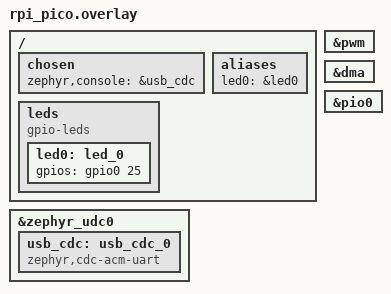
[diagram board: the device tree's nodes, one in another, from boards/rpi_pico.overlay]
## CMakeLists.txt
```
cmake_minimum_required(VERSION 3.20.0)

find_package(Zephyr REQUIRED HINTS $ENV{ZEPHYR_BASE})
project(pico_mplay_zephyr)

target_sources(app PRIVATE src/main.c src/mod_player.c)

# Embed the MOD file as flash data (mod_data[] / mod_data_len), generated at
# build time into the build directory rather than committing a ~6x larger
# generated header - same approach as ~/devel/pico_mplay. Swap songs by
# changing MOD_SOURCE_FILE.
set(MOD_SOURCE_FILE ${CMAKE_CURRENT_LIST_DIR}/AXEL_F.MOD)
set(MOD_DATA_HEADER ${CMAKE_CURRENT_BINARY_DIR}/mod_data.h)
add_custom_command(
        OUTPUT ${MOD_DATA_HEADER}
        COMMAND ${CMAKE_COMMAND} -E copy ${MOD_SOURCE_FILE} mod_data
        COMMAND sh -c "xxd -i mod_data | sed \
                -e 's/^unsigned char mod_data\\[\\]/static const unsigned char mod_data[]/' \
                -e 's/^unsigned int mod_data_len/static const unsigned int mod_data_len/' \
                > mod_data.h"
        WORKING_DIRECTORY ${CMAKE_CURRENT_BINARY_DIR}
        DEPENDS ${MOD_SOURCE_FILE}
        VERBATIM
        COMMENT "Generating mod_data.h from ${MOD_SOURCE_FILE}"
)
add_custom_target(mod_data_header DEPENDS ${MOD_DATA_HEADER})
add_dependencies(app mod_data_header)
target_include_directories(app PRIVATE ${CMAKE_CURRENT_BINARY_DIR})
```

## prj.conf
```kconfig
CONFIG_GPIO=y
CONFIG_PWM=y
CONFIG_DMA=y

# For serial console (as of autumn 2026)
CONFIG_USB_DEVICE_STACK_NEXT=y
CONFIG_CDC_ACM_SERIAL_INITIALIZE_AT_BOOT=y
CONFIG_STDOUT_CONSOLE=y
CONFIG_SERIAL=y
CONFIG_UART_LINE_CTRL=y
CONFIG_USBD_CDC_ACM_CLASS=y
```

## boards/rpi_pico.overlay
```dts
/*
 * Neither rpi_pico nor rpi_pico2 define a `led0` alias in this Zephyr tree,
 * so the standard samples/basic/blinky-style DT_ALIAS(led0) pattern needs
 * this one-time overlay. GPIO25 is the onboard LED on the plain (non-W)
 * Pico 2, same pin as the original Pico.
 */
#include <zephyr/dt-bindings/gpio/gpio.h>

/ {
    chosen {
        zephyr,console = &usb_cdc;
    };

    aliases {
		led0 = &led0;
	};

	leds {
		compatible = "gpio-leds";
		led0: led_0 {
			gpios = <&gpio0 25 GPIO_ACTIVE_HIGH>;
		};
	};
};

/*
 * Both disabled by default; pinctrl (GPIO25 -> PWM slice 4 channel B) is
 * already wired up at board level (pwm_ch4b_default), so enabling status is
 * all that's needed here.
 */
&pwm {
	status = "okay";
};

&dma {
	status = "okay";
};

/*
 * No pinctrl group needed here: i2s_out_program_init()-equivalent code in
 * main.c routes GP26/27/28 to the PIO block via raw pico_gpio_init() calls
 * (same as the bare-metal version), bypassing Zephyr's pinctrl subsystem
 * entirely for this peripheral.
 */
&pio0 {
	status = "okay";
};

&zephyr_udc0 {
    usb_cdc: usb_cdc_0 {
        compatible = "zephyr,cdc-acm-uart";
    };
};
```

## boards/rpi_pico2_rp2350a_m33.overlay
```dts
/*
 * Neither rpi_pico nor rpi_pico2 define a `led0` alias in this Zephyr tree,
 * so the standard samples/basic/blinky-style DT_ALIAS(led0) pattern needs
 * this one-time overlay. GPIO25 is the onboard LED on the plain (non-W)
 * Pico 2, same pin as the original Pico.
 */
#include <zephyr/dt-bindings/gpio/gpio.h>

/ {
	aliases {
		led0 = &led0;
	};

	leds {
		compatible = "gpio-leds";
		led0: led_0 {
			gpios = <&gpio0 25 GPIO_ACTIVE_HIGH>;
		};
	};
};

/*
 * Both disabled by default; pinctrl (GPIO25 -> PWM slice 4 channel B) is
 * already wired up at board level (pwm_ch4b_default), so enabling status is
 * all that's needed here.
 */
&pwm {
	status = "okay";
};

&dma {
	status = "okay";
};
```

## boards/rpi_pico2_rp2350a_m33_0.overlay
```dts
/*
 * Neither rpi_pico nor rpi_pico2 define a `led0` alias in this Zephyr tree,
 * so the standard samples/basic/blinky-style DT_ALIAS(led0) pattern needs
 * this one-time overlay. GPIO25 is the onboard LED on the plain (non-W)
 * Pico 2, same pin as the original Pico.
 */
#include <zephyr/dt-bindings/gpio/gpio.h>

/ {
	chosen {
		zephyr,console = &usb_cdc;
	};

	aliases {
		led0 = &led0;
	};

	leds {
		compatible = "gpio-leds";
		led0: led_0 {
			gpios = <&gpio0 25 GPIO_ACTIVE_HIGH>;
		};
	};
};

/*
 * Both disabled by default; pinctrl (GPIO25 -> PWM slice 4 channel B) is
 * already wired up at board level (pwm_ch4b_default), so enabling status is
 * all that's needed here.
 */
&pwm {
	status = "okay";
};

&dma {
	status = "okay";
};

/*
 * No pinctrl group needed here: i2s_out_program_init()-equivalent code in
 * main.c routes GP26/27/28 to the PIO block via raw pico_gpio_init() calls
 * (same as the bare-metal version), bypassing Zephyr's pinctrl subsystem
 * entirely for this peripheral.
 */
&pio0 {
	status = "okay";
};

&zephyr_udc0 {
	usb_cdc: usb_cdc_0 {
		compatible = "zephyr,cdc-acm-uart";
	};
};
```

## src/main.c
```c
/*
 * Step 4: real Amiga MOD playback, same PIO/DMA I2S backend as step 3.
 *
 * mod_player.c/h (ported here unmodified from ~/devel/pico_mplay - it was
 * already pure C with zero pico-sdk/Zephyr dependency) replaces the sweep
 * generator as the sample source. mod_player_produce() doesn't care how
 * many samples are requested or when, so it drops straight into
 * fill_buffer() exactly like it does in the bare-metal version - the only
 * change from step 3 is what fill_buffer() calls to get mono samples
 * before packing them into stereo I2S frames.
 *
 * Reuses ~/devel/pico_mplay's i2s_out.pio verbatim (see i2s_out_pio.h) via
 * Zephyr's pio_rpi_pico driver, which handles state-machine allocation and
 * program loading but - like Zephyr's PWM API in step 2 - has no concept
 * of a DMA-fed streaming consumer for a custom PIO program. So the pattern
 * is the same as step 2: Zephyr's driver does the one-time setup (here,
 * allocating the SM and loading the program), then DMA is configured and
 * manually re-armed from its own completion callback via zephyr/drivers/dma.h,
 * writing 32-bit stereo frames directly into the PIO's TX FIFO register.
 *
 * dma_done() (the DMA completion ISR) only re-arms DMA and does bookkeeping
 * (consumed/filled sequence counters, an underrun count, and the PIO's own
 * TXSTALL flag) - it does not render. Rendering (fill_buffer(), i.e. the
 * whole 4-channel mixer) runs in main()'s thread, woken by a semaphore the
 * ISR gives, so a slow render can't block other same/lower-priority
 * interrupts (e.g. USB CDC) for the whole mixer's runtime. See the
 * consumed/filled comment near their declarations for why a single flag
 * isn't enough, and ~/devel/pico_dma/pico_mplay.c for the bare-metal
 * version of the same scheme this was ported from.
 *
 * pio_gpio_init()/pio_sm_set_consecutive_pindirs() (raw pico-sdk calls, same
 * as the bare-metal version) handle routing GP26/27/28 to the PIO block
 * directly - no Zephyr pinctrl devicetree group needed for this peripheral.
 *
 * The MOD file (mod_data[]/mod_data_len) is generated at build time from
 * AXEL_F.MOD into the build directory - see CMakeLists.txt.
 */

#include <zephyr/kernel.h>
#include <zephyr/device.h>
#include <zephyr/drivers/dma.h>
#include <zephyr/sys/barrier.h>
#include <zephyr/drivers/misc/pio_rpi_pico/pio_rpi_pico.h>
#if defined(CONFIG_SOC_SERIES_RP2350)
#include <zephyr/dt-bindings/dma/rpi-pico-dma-rp2350.h>
#else
#include <zephyr/dt-bindings/dma/rpi-pico-dma-rp2040.h>
#endif
#include <hardware/pio.h>
/*
 * pico-sdk's hardware/pio.h #defines pio0/pio1 as its own PIO-instance
 * singletons (`#define pio0 pio0_hw`), which collides with Zephyr's
 * DT_NODELABEL(pio0) token-pasting macro below - both want the bare
 * identifier. We never use the pico-sdk singletons (PIO comes from
 * pio_rpi_pico_get_pio() instead), so just get them out of the way.
 */
#undef pio0
#undef pio1
#include <hardware/clocks.h>

#include "i2s_out_pio.h"
#include "mod_player.h"
#include "mod_data.h"

#define PIN_BCLK 26   /* WS/LRCLK is PIN_BCLK+1 (GP27) - side-set requirement */
#define PIN_DATA 28

#define SAMPLE_RATE_HZ   48000u
#define BITS_PER_CHANNEL 16u

#define BUF_LEN 256   /* stereo frames/buffer */

static const struct device *dma_dev;
static PIO pio;
static size_t sm;
static uint32_t dma_channel;
static volatile uint32_t *txf;

static uint32_t buf[2][BUF_LEN];

/* Buffers are numbered by sequence: buffer k lives in buf[k & 1]. The DMA
 * ISR (dma_done()) advances `consumed` (buffers DMA has finished) and
 * re-arms the next one immediately; the main thread advances `filled`
 * (buffers completely rendered) only *after* rendering, so comparing the
 * two counters catches every underrun - including DMA reaching a buffer
 * the main thread is still mid-render on. Mirrors the bare-metal version's
 * consumed/filled scheme in ~/devel/pico_dma/pico_mplay.c, and for the same
 * reason: a single "fill_needed" flag cleared before rendering starts can
 * miss/lose events across the ISR/thread boundary.
 *
 * Unlike bare-metal, rendering used to happen directly inside dma_done()
 * itself (the DMA completion ISR) - the entire 4-channel mixer ran with
 * this interrupt's priority blocked for however long mod_player_produce()
 * took, every 5.33ms. That's moved to the main thread below so a slow
 * render can't stall other interrupts (USB CDC console included).
 */
static volatile uint32_t consumed;   /* ISR-owned */
static volatile uint32_t filled;     /* main-thread-owned */
static volatile uint32_t underrun_count;

/* Hardware's own "FIFO ran dry" flag (PIO's sticky per-SM TXSTALL bit),
 * independent of the consumed/filled bookkeeping above - catches cases the
 * software counters can't, such as the main thread being descheduled
 * entirely rather than merely running behind.
 */
static volatile uint32_t txstall_count;
static volatile uint32_t dma_error_count;

K_SEM_DEFINE(fill_needed_sem, 0, 1);

static struct PlayerState player;
static int16_t mono_scratch[BUF_LEN];

/* Renders BUF_LEN mono samples from the MOD mixer, then packs each one into
 * a stereo I2S frame (same value in both channels) matching what
 * i2s_out.pio expects from the FIFO: [left:16][right:16] in one 32-bit word.
 */
static void fill_buffer(uint32_t *b)
{
	mod_player_produce(&player, mono_scratch, BUF_LEN);
	for (int i = 0; i < BUF_LEN; i++) {
		uint16_t sample = (uint16_t)mono_scratch[i];
		b[i] = ((uint32_t)sample << 16) | sample;
	}
}

/* Fires once DMA finishes streaming one of the two buffers. Immediately
 * hands the next buffer (already rendered last time round) back to DMA to
 * keep the gap minimal, bumps the sequence counters, and wakes the main
 * thread to render the buffer that just finished playing - it does *not*
 * render here itself (see the consumed/filled comment above for why).
 */
static void dma_done(const struct device *dev, void *user_data, uint32_t channel, int status);

/* File-scope so dma_done() can re-arm through them (see arm_next_buffer()). */
static struct dma_block_config dma_block = {
	.block_size = BUF_LEN * sizeof(uint32_t),
	.source_addr_adj = DMA_ADDR_ADJ_INCREMENT,
	.dest_addr_adj = DMA_ADDR_ADJ_NO_CHANGE,
};
static struct dma_config dma_cfg = {
	.channel_direction = MEMORY_TO_PERIPHERAL,
	.source_data_size = 4,
	.dest_data_size = 4,
	.source_burst_length = 1,
	.dest_burst_length = 1,
	.block_count = 1,
	.head_block = &dma_block,
	.dma_callback = dma_done,
};

/* Points the (idle) channel at buffer `next & 1` and triggers it - exactly
 * once. This used to be dma_reload() + dma_start(), but on the rpi_pico DMA
 * driver *both* call dma_channel_configure(..., trigger=true), so the second
 * rewrote READ_ADDR/TRANS_COUNT/CTRL_TRIG on a channel already running,
 * racing its DREQ. In xiao_rp2040_mplay (same code, PWM-paced) that race
 * permanently stalled the DMA once every few seconds to minutes; the
 * bare-metal pico_dma never had it (one dma_channel_transfer_from_buffer_now()
 * per buffer). dma_config() only stores settings in the driver - no register
 * writes - so config + start is a single trigger on an idle channel.
 */
static void arm_next_buffer(uint32_t next)
{
	dma_block.source_address = (uintptr_t)buf[next & 1];
	dma_config(dma_dev, dma_channel, &dma_cfg);
	dma_start(dma_dev, dma_channel);
}

static void dma_done(const struct device *dev, void *user_data, uint32_t channel, int status)
{
	ARG_UNUSED(dev);
	ARG_UNUSED(user_data);
	ARG_UNUSED(channel);
	if (status < 0) {
		/* Count it but keep going - returning here without re-arming
		 * silenced audio permanently.
		 */
		dma_error_count++;
	}

	uint32_t next = consumed + 1;   /* sequence number of the buffer to play now */

	arm_next_buffer(next);

	/* `next` must be completely rendered by now (filled > next). If the
	 * main thread hasn't finished it - or hasn't started - DMA is about
	 * to play stale data.
	 */
	if ((int32_t)(filled - next) <= 0) {   /* signed diff: wrap-safe */
		underrun_count++;
	}
	consumed = next;

	uint32_t stall_bit = 1u << (PIO_FDEBUG_TXSTALL_LSB + sm);
	if (pio->fdebug & stall_bit) {
		/* The very first call is special: pio_sm_set_enabled() runs
		 * before dma_start()'s first bus transfer has necessarily
		 * landed in the FIFO, so the SM always stalls briefly at
		 * boot waiting for that first word - not a real underrun.
		 * By the time a whole buffer's worth of playback has elapsed
		 * (i.e. we're here at all), that transient is long over, so
		 * checking here instead of right after the initial
		 * dma_start() in main() is race-free: clear and don't count
		 * once, then count for real from then on.
		 */
		static bool first_call = true;

		if (!first_call) {
			txstall_count++;
		}
		first_call = false;
		pio->fdebug = stall_bit;   /* write-1-to-clear */
	}

	k_sem_give(&fill_needed_sem);
}

int main(void)
{
	/* &pio0 and &dma are enabled in the per-board overlays under boards/;
	 * pio_dev only exists to allocate a state machine and get the raw
	 * PIO handle - everything else is driven through direct pico-sdk
	 * calls below.
	 */
	const struct device *pio_dev = DEVICE_DT_GET(DT_NODELABEL(pio0));

	dma_dev = DEVICE_DT_GET(DT_NODELABEL(dma));

	if (!device_is_ready(pio_dev) || !device_is_ready(dma_dev)) {
		printk("pio or dma device not ready\n");
		return 0;
	}

	pio = pio_rpi_pico_get_pio(pio_dev);
	if (pio_rpi_pico_allocate_sm(pio_dev, &sm) != 0) {
		printk("no free PIO state machine\n");
		return 0;
	}

	/* Load the program bytes from i2s_out_pio.h into PIO instruction
	 * memory and get back where it landed (offset).
	 */
	uint offset = pio_add_program(pio, RPI_PICO_PIO_GET_PROGRAM(i2s_out));

	/* i2s_out.pio spends 2 PIO cycles per bit and 2*BITS_PER_CHANNEL bits
	 * per stereo frame, so the SM must run at SAMPLE_RATE_HZ * 4 *
	 * BITS_PER_CHANNEL to make one frame take exactly one sample period -
	 * same formula as the bare-metal version.
	 */
	float clkdiv = (float)clock_get_hz(clk_sys) / (float)(SAMPLE_RATE_HZ * 4u * BITS_PER_CHANNEL);

	/* Route GP26/27 (BCLK/WS) and GP28 (DATA) to this PIO block and set
	 * them as outputs - raw pico-sdk calls, no Zephyr pinctrl involved.
	 */
	pio_gpio_init(pio, PIN_BCLK);
	pio_gpio_init(pio, PIN_BCLK + 1);
	pio_gpio_init(pio, PIN_DATA);
	pio_sm_set_consecutive_pindirs(pio, sm, PIN_BCLK, 2, true);
	pio_sm_set_consecutive_pindirs(pio, sm, PIN_DATA, 1, true);

	/* Same SM configuration as i2s_out_program_init() in the bare-metal
	 * project's generated header - reconstructed by hand here since
	 * Zephyr's generic RPI_PICO_PIO_DEFINE_PROGRAM macro only captures
	 * wrap_target/wrap, not a program-specific default-config helper.
	 */
	pio_sm_config c = pio_get_default_sm_config();
	sm_config_set_wrap(&c, offset + RPI_PICO_PIO_GET_WRAP_TARGET(i2s_out),
			    offset + RPI_PICO_PIO_GET_WRAP(i2s_out));
	sm_config_set_sideset(&c, 2, false, false);          /* BCLK+WS, 2 bits */
	sm_config_set_sideset_pins(&c, PIN_BCLK);
	sm_config_set_out_pins(&c, PIN_DATA, 1);
	sm_config_set_out_shift(&c, false, true, 32);        /* MSB-first, autopull every 32 bits */
	sm_config_set_fifo_join(&c, PIO_FIFO_JOIN_TX);       /* 8-deep TX FIFO, no RX needed */
	sm_config_set_clkdiv(&c, clkdiv);
	pio_sm_init(pio, sm, offset, &c);

	if (mod_player_init(&player, mod_data, mod_data_len) != 0) {
		printk("mod_player_init failed - bad or unrecognized MOD data\n");
		return 0;
	}

	/* Pre-fill both buffers before DMA/PIO start moving, then remember
	 * the PIO's TX FIFO address as the fixed DMA destination.
	 */
	fill_buffer(buf[0]);
	fill_buffer(buf[1]);
	filled = 2;
	txf = &pio->txf[sm];

	int ch = dma_request_channel(dma_dev, NULL);
	if (ch < 0) {
		printk("no free dma channel\n");
		return 0;
	}
	dma_channel = (uint32_t)ch;

	/* One 32-bit stereo frame per transfer, source address walks buf[0],
	 * destination is the PIO FIFO register and never moves.
	 */
	dma_block.dest_address = (uintptr_t)txf;
	/* dma_slot paces the channel from the PIO SM's own TX DREQ (fires
	 * whenever the FIFO has room), same DREQ pio_get_dreq() would give
	 * the bare-metal version - just wrapped for Zephyr's dma_slot field.
	 */
	dma_cfg.dma_slot = RPI_PICO_DMA_DREQ_TO_SLOT(pio_get_dreq(pio, sm, true));
	dma_block.source_address = (uintptr_t)buf[0];
	dma_config(dma_dev, dma_channel, &dma_cfg);

	/* Enable the SM before the first DMA transfer, same order as the
	 * bare-metal version, so it's already waiting on the FIFO rather
	 * than racing the first transfer.
	 */
	pio_sm_set_enabled(pio, sm, true);
	dma_start(dma_dev, dma_channel);
	/* The SM stalls once at boot, waiting for the first buffer's data to
	 * actually land in the FIFO (dma_start() only arms the transfer, the
	 * bus transaction itself is asynchronous) - that expected transient
	 * is absorbed race-free inside dma_done()'s first call instead of
	 * being cleared here, see the comment there.
	 */

	printk("mod player running\n");
	int64_t next_report = k_uptime_get() + 1000;
	while (1) {
		/* Woken by dma_done() (or times out - not otherwise fatal) so
		 * the report below still fires ~1/s even if nothing is due
		 * to render this tick.
		 */
		k_sem_take(&fill_needed_sem, K_MSEC(100));

		/* Buffer `filled` may be rendered once buffer `filled - 2`
		 * (same slot) has been consumed, i.e. filled < consumed + 2.
		 */
		while ((int32_t)(consumed + 2 - filled) > 0) {
			fill_buffer(buf[filled & 1]);
			barrier_dmem_fence_full();   /* buffer stores land before the count says "done" */
			filled++;
		}

		/* Software-only sanity check, same as bare-metal: position/
		 * row should visibly advance through the song regardless of
		 * whether anything is audible, plus both underrun indicators
		 * (software: render ran late; hardware: FIFO actually ran
		 * dry) so a symptom like an occasional pop can be attributed
		 * to this DMA/render path or ruled out in favour of something
		 * else (e.g. a power-supply issue affecting the amp/DAC).
		 */
		if (k_uptime_get() >= next_report) {
			printk("pos=%d row=%d underruns=%u txstall=%u dma_errs=%u\n",
			       player.current_position, player.current_row,
			       underrun_count, txstall_count, dma_error_count);
			next_report += 1000;
		}
	}
	return 0;
}
```

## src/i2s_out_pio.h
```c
#pragma once

/*
 * Compiled PIO program for i2s_out.pio from ~/devel/pico_mplay (same
 * author, MIT). Zephyr has no pioasm/CMake integration - PIO programs must
 * be embedded as pre-assembled opcode arrays (see RPI_PICO_PIO_DEFINE_PROGRAM
 * below) - so rather than hand-assembling from the ISA reference, these
 * bytes are lifted directly from that project's build/i2s_out.pio.h
 * (pioasm's own output), which is already correct and verified on real
 * hardware, including the BCLK falling/rising-edge fix found there.
 * Regenerate this file from there (rebuild pico_mplay, then
 * `cat build/i2s_out.pio.h`) if that program ever changes.
 *
 * wrap_target=0, wrap=7, side-set width=2 (BCLK+WS) - the generic
 * RPI_PICO_PIO_DEFINE_PROGRAM macro captures the first two; side-set width
 * isn't part of it and has to be set manually via sm_config_set_sideset()
 * wherever this program's default config is built (see main.c).
 *
 * Original .pio source, for reference (see i2s_out.pio in the bare-metal
 * repo for the full explanation of the I2S falling/rising-edge timing this
 * implements - only the short version is repeated here):
 *
 *   .program i2s_out
 *   .side_set 2
 *
 *   .define BITS_PER_CHANNEL 16
 *
 *   .wrap_target
 *   left_word:
 *       set x, (BITS_PER_CHANNEL - 2)  side 0b01   ; BCLK high: samples the previous frame's last bit
 *   left_loop:
 *       out pins, 1                    side 0b00   ; new bit onto DATA, BCLK low (setup)
 *       jmp x-- left_loop              side 0b01   ; BCLK high: receiver samples this bit
 *       out pins, 1                    side 0b10   ; last (16th) left bit; WS flips to "right", BCLK low
 *   right_word:
 *       set x, (BITS_PER_CHANNEL - 2)  side 0b11   ; BCLK high: samples left channel's last bit
 *   right_loop:
 *       out pins, 1                    side 0b10   ; new bit onto DATA, BCLK low (setup)
 *       jmp x-- right_loop             side 0b11   ; BCLK high: receiver samples this bit
 *       out pins, 1                    side 0b00   ; last (16th) right bit; WS flips to "left", BCLK low
 *   .wrap
 *
 * Instruction-by-instruction mapping to the opcodes below (same order):
 *
 *   0xe82e  set  x, 14      side 1   (left_word)
 *   0x6001  out  pins, 1    side 0   (left_loop)
 *   0x0841  jmp  x--, 1     side 1   (left_loop, target = instruction 1)
 *   0x7001  out  pins, 1    side 2   (right_word's leading bit, WS -> right)
 *   0xf82e  set  x, 14      side 3   (right_word)
 *   0x7001  out  pins, 1    side 2   (right_loop)
 *   0x1845  jmp  x--, 5     side 3   (right_loop, target = instruction 5)
 *   0x6001  out  pins, 1    side 0   (last right bit, WS -> left, wraps to 0)
 */

#include <zephyr/drivers/misc/pio_rpi_pico/pio_rpi_pico.h>

RPI_PICO_PIO_DEFINE_PROGRAM(i2s_out, 0, 7,
	0xe82e,
	0x6001,
	0x0841,
	0x7001,
	0xf82e,
	0x7001,
	0x1845,
	0x6001
);
```

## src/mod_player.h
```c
// MOD player core, ported from ~/devel/mplay/mod_player.c (same author, MIT).
// Parsing, effects, and mixing logic is reused near-verbatim; only the
// driving loop and the byte-order-sensitive sample-header handling changed,
// see mod_player.c for why.
#pragma once

#include <stdbool.h>
#include <stddef.h>
#include <stdint.h>

#define MOD_MAX_SAMPLES      32   // 1-indexed: slot 0 unused, 1..31 are real samples
#define MOD_NUM_CHANNELS     4
#define MOD_ROWS_PER_PATTERN 64

struct __attribute__((packed)) ModSample {
    char name[22];
    uint16_t length_words;
    int8_t fine_tune;
    uint8_t volume;
    uint16_t repeat_offset;
    uint16_t repeat_length;
};

struct __attribute__((packed)) ModHeader {
    char title[20];
    struct ModSample samples[31];
    uint8_t pattern_count;
    uint8_t idk;
    uint8_t patterns[128];
    char magic[4];
};

struct ModNote {
    uint8_t  instrument;
    uint16_t period;
    uint8_t  effect;
    uint8_t  effect_arg;
};

struct Channel {
    const int8_t *sample_data;
    uint32_t sample_length;
    uint32_t loop_start;
    uint32_t loop_length;
    float position;
    float increment;
    uint16_t period;
    uint8_t volume;
    uint8_t instrument;
    uint16_t target_period;
    uint8_t portamento_speed;
    uint8_t vibrato_speed;
    uint8_t vibrato_depth;
    uint8_t vibrato_pos;
    uint8_t vibrato_waveform;
    uint8_t tremolo_speed;
    uint8_t tremolo_depth;
    uint8_t tremolo_pos;
    uint8_t tremolo_waveform;
    int8_t tremolo_delta;
    int8_t finetune;
    uint8_t offset_memory;
};

struct PlayerState {
    const void *mod_data;
    size_t mod_size;
    const struct ModHeader *header;
    const uint8_t *pattern_data;
    const int8_t *sample_base;

    // Precomputed per-sample metadata. The source MOD may live in flash
    // (read-only XIP memory), so unlike the original desktop player these
    // are computed once here rather than byte-swapped in place over the
    // source buffer - see mod_player.c's mod_player_init().
    const int8_t *sample_offsets[MOD_MAX_SAMPLES];
    uint32_t sample_lengths[MOD_MAX_SAMPLES];
    uint32_t sample_loop_start[MOD_MAX_SAMPLES];
    uint32_t sample_loop_length[MOD_MAX_SAMPLES];
    int8_t sample_finetune[MOD_MAX_SAMPLES];

    int speed;
    int tempo;
    int current_position;
    int current_row;
    int current_tick;
    struct Channel channels[MOD_NUM_CHANNELS];
    int break_row;
    int break_position;
    int pattern_delay;
    int loop_row;
    int loop_count;

    // Incremental-render state: replaces the desktop player's nested
    // position/row/tick loop so samples can be pulled in arbitrary-sized
    // chunks (DMA buffer sized, not tick sized) - see mod_player_produce().
    struct ModNote current_notes[MOD_NUM_CHANNELS];
    int total_ticks_in_row;
    int samples_per_tick;
    int tick_samples_remaining;
    bool started;
    bool visited[128 * MOD_ROWS_PER_PATTERN];
};

// Parses a MOD file already sitting in memory (flash or RAM). Returns 0 on
// success, -1 if the data is too small, unrecognized, or corrupt (pattern
// data extending past the end of the buffer).
int mod_player_init(struct PlayerState *ps, const uint8_t *mod_data, size_t mod_size);

// Renders exactly `n` mono 16-bit samples at 48 kHz, advancing playback
// state as needed - including across tick/row/pattern boundaries within a
// single call, and looping back to the start of the song when it ends.
// `n` does not need to align with tick or row boundaries in any way.
void mod_player_produce(struct PlayerState *ps, int16_t *out, int n);
```
